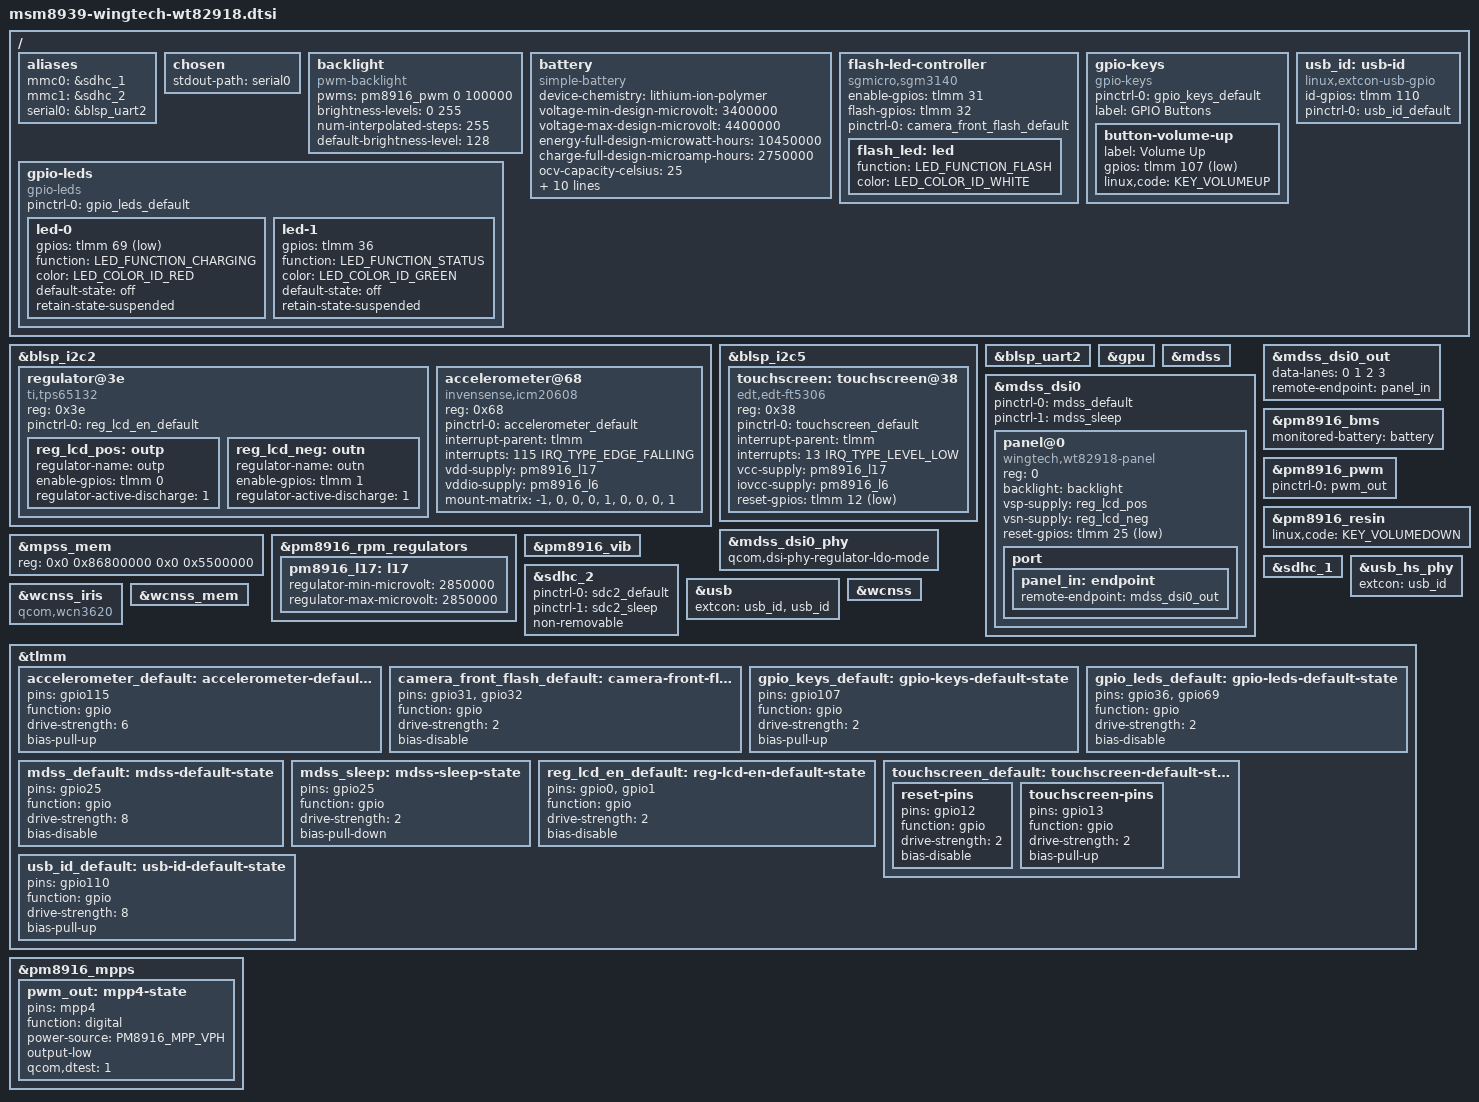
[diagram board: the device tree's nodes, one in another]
// SPDX-License-Identifier: GPL-2.0-only

#include "msm8939-pm8916.dtsi"
#include "msm8916-modem-qdsp6.dtsi"

#include <dt-bindings/gpio/gpio.h>
#include <dt-bindings/leds/common.h>
#include <dt-bindings/pinctrl/qcom,pmic-mpp.h>

/ {
	aliases {
		mmc0 = &sdhc_1; /* eMMC */
		mmc1 = &sdhc_2; /* SD card */
		serial0 = &blsp_uart2;
	};

	chosen {
		stdout-path = "serial0";
	};

	backlight: backlight {
		compatible = "pwm-backlight";
		pwms = <&pm8916_pwm 0 100000>;
		brightness-levels = <0 255>;
		num-interpolated-steps = <255>;
		default-brightness-level = <128>;
	};

	battery: battery {
		compatible = "simple-battery";
		device-chemistry = "lithium-ion-polymer";
		voltage-min-design-microvolt = <3400000>;
		voltage-max-design-microvolt = <4400000>;
		energy-full-design-microwatt-hours = <10450000>;
		charge-full-design-microamp-hours = <2750000>;

		ocv-capacity-celsius = <25>;
		ocv-capacity-table-0 = <4365000 100>, <4314000 95>, <4253000 90>,
			<4194000 85>, <4137000 80>, <4084000 75>, <4032000 70>,
			<3983000 65>, <3936000 60>, <3888000 55>, <3852000 50>,
			<3826000 45>, <3806000 40>, <3789000 35>, <3779000 30>,
			<3769000 25>, <3740000 20>, <3712000 16>, <3702000 13>,
			<3692000 11>, <3690000 10>, <3688000 9>, <3687000 8>,
			<3685000 7>, <3680000 6>, <3663000 5>, <3618000 4>,
			<3558000 3>, <3478000 2>, <3352000 1>, <3000000 0>;
	};

	flash-led-controller {
		compatible = "sgmicro,sgm3140";
		enable-gpios = <&tlmm 31 GPIO_ACTIVE_HIGH>;
		flash-gpios = <&tlmm 32 GPIO_ACTIVE_HIGH>;

		pinctrl-0 = <&camera_front_flash_default>;
		pinctrl-names = "default";

		flash_led: led {
			function = LED_FUNCTION_FLASH;
			color = <LED_COLOR_ID_WHITE>;
		};
	};

	gpio-keys {
		compatible = "gpio-keys";

		pinctrl-0 = <&gpio_keys_default>;
		pinctrl-names = "default";

		label = "GPIO Buttons";

		button-volume-up {
			label = "Volume Up";
			gpios = <&tlmm 107 GPIO_ACTIVE_LOW>;
			linux,code = <KEY_VOLUMEUP>;
		};
	};

	gpio-leds {
		compatible = "gpio-leds";

		pinctrl-0 = <&gpio_leds_default>;
		pinctrl-names = "default";

		led-0 {
			gpios = <&tlmm 69 GPIO_ACTIVE_LOW>;
			function = LED_FUNCTION_CHARGING;
			color = <LED_COLOR_ID_RED>;
			default-state = "off";
			retain-state-suspended;
		};

		led-1 {
			gpios = <&tlmm 36 GPIO_ACTIVE_HIGH>;
			function = LED_FUNCTION_STATUS;
			color = <LED_COLOR_ID_GREEN>;
			default-state = "off";
			retain-state-suspended;
		};
	};

	usb_id: usb-id {
		compatible = "linux,extcon-usb-gpio";
		id-gpios = <&tlmm 110 GPIO_ACTIVE_HIGH>;
		pinctrl-0 = <&usb_id_default>;
		pinctrl-names = "default";
	};
};

&blsp_i2c2 {
	status = "okay";

	regulator@3e {
		compatible = "ti,tps65132";
		reg = <0x3e>;

		pinctrl-0 = <&reg_lcd_en_default>;
		pinctrl-names = "default";

		reg_lcd_pos: outp {
			regulator-name = "outp";
			enable-gpios = <&tlmm 0 GPIO_ACTIVE_HIGH>;
			regulator-active-discharge = <1>;
		};

		reg_lcd_neg: outn {
			regulator-name = "outn";
			enable-gpios = <&tlmm 1 GPIO_ACTIVE_HIGH>;
			regulator-active-discharge = <1>;
		};
	};

	accelerometer@68 {
		compatible = "invensense,icm20608";
		reg = <0x68>;

		pinctrl-0 = <&accelerometer_default>;
		pinctrl-names = "default";

		interrupt-parent = <&tlmm>;
		interrupts = <115 IRQ_TYPE_EDGE_FALLING>;

		vdd-supply = <&pm8916_l17>;
		vddio-supply = <&pm8916_l6>;

		mount-matrix = "-1",  "0", "0",
			       "0", "1", "0",
			       "0",  "0", "1";
	};
};

&blsp_i2c5 {
	status = "okay";

	touchscreen: touchscreen@38 {
		/* actually FT5336 */
		compatible = "edt,edt-ft5306";
		reg = <0x38>;

		pinctrl-0 = <&touchscreen_default>;
		pinctrl-names = "default";

		interrupt-parent = <&tlmm>;
		interrupts = <13 IRQ_TYPE_LEVEL_LOW>;

		vcc-supply = <&pm8916_l17>;
		iovcc-supply = <&pm8916_l6>;

		reset-gpios = <&tlmm 12 GPIO_ACTIVE_LOW>;
	};
};

&blsp_uart2 {
	status = "okay";
};

&gpu {
	status = "okay";
};

&mdss {
	status = "okay";
};

&mdss_dsi0 {
	pinctrl-0 = <&mdss_default>;
	pinctrl-1 = <&mdss_sleep>;
	pinctrl-names = "default", "sleep";
	status = "okay";

	panel@0 {
		compatible = "wingtech,wt82918-panel";
		reg = <0>;

		backlight = <&backlight>;
		vsp-supply = <&reg_lcd_pos>;
		vsn-supply = <&reg_lcd_neg>;
		reset-gpios = <&tlmm 25 GPIO_ACTIVE_LOW>;

		port {
			panel_in: endpoint {
				remote-endpoint = <&mdss_dsi0_out>;
			};
		};
	};
};

&mdss_dsi0_out {
	data-lanes = <0 1 2 3>;
	remote-endpoint = <&panel_in>;
};

&mdss_dsi0_phy {
	qcom,dsi-phy-regulator-ldo-mode;
	status = "okay";
};

&mpss_mem {
	reg = <0x0 0x86800000 0x0 0x5500000>;
};

&pm8916_bms {
	monitored-battery = <&battery>;
	status = "okay";
};

&pm8916_pwm {
	pinctrl-0 = <&pwm_out>;
	pinctrl-names = "default";
	status = "okay";
};

&pm8916_resin {
	linux,code = <KEY_VOLUMEDOWN>;
	status = "okay";
};

&pm8916_rpm_regulators {
	pm8916_l17: l17 {
		regulator-min-microvolt = <2850000>;
		regulator-max-microvolt = <2850000>;
	};
};

&pm8916_vib {
	status = "okay";
};

&sdhc_1 {
	status = "okay";
};

&sdhc_2 {
	pinctrl-0 = <&sdc2_default>;
	pinctrl-1 = <&sdc2_sleep>;
	pinctrl-names = "default", "sleep";
	non-removable;
	status = "okay";
};

&usb {
	extcon = <&usb_id>, <&usb_id>;
	status = "okay";
};

&usb_hs_phy {
	extcon = <&usb_id>;
};

&wcnss {
	status = "okay";
};

&wcnss_iris {
	compatible = "qcom,wcn3620";
};

&wcnss_mem {
	status = "okay";
};

&tlmm {
	accelerometer_default: accelerometer-default-state {
		pins = "gpio115";
		function = "gpio";
		drive-strength = <6>;
		bias-pull-up;
	};

	camera_front_flash_default: camera-front-flash-default-state {
		pins = "gpio31", "gpio32";
		function = "gpio";
		drive-strength = <2>;
		bias-disable;
	};

	gpio_keys_default: gpio-keys-default-state {
		pins = "gpio107";
		function = "gpio";
		drive-strength = <2>;
		bias-pull-up;
	};

	gpio_leds_default: gpio-leds-default-state {
		pins = "gpio36", "gpio69";
		function = "gpio";
		drive-strength = <2>;
		bias-disable;
	};

	mdss_default: mdss-default-state {
		pins = "gpio25";
		function = "gpio";
		drive-strength = <8>;
		bias-disable;
	};

	mdss_sleep: mdss-sleep-state {
		pins = "gpio25";
		function = "gpio";
		drive-strength = <2>;
		bias-pull-down;
	};

	reg_lcd_en_default: reg-lcd-en-default-state {
		pins = "gpio0", "gpio1";
		function = "gpio";
		drive-strength = <2>;
		bias-disable;
	};

	touchscreen_default: touchscreen-default-state {
		reset-pins {
			pins = "gpio12";
			function = "gpio";
			drive-strength = <2>;
			bias-disable;
		};

		touchscreen-pins {
			pins = "gpio13";
			function = "gpio";
			drive-strength = <2>;
			bias-pull-up;
		};
	};

	usb_id_default: usb-id-default-state {
		pins = "gpio110";
		function = "gpio";
		drive-strength = <8>;
		bias-pull-up;
	};
};

&pm8916_mpps {
	pwm_out: mpp4-state {
		pins = "mpp4";
		function = "digital";
		power-source = <PM8916_MPP_VPH>;
		output-low;
		qcom,dtest = <1>;
	};
};
